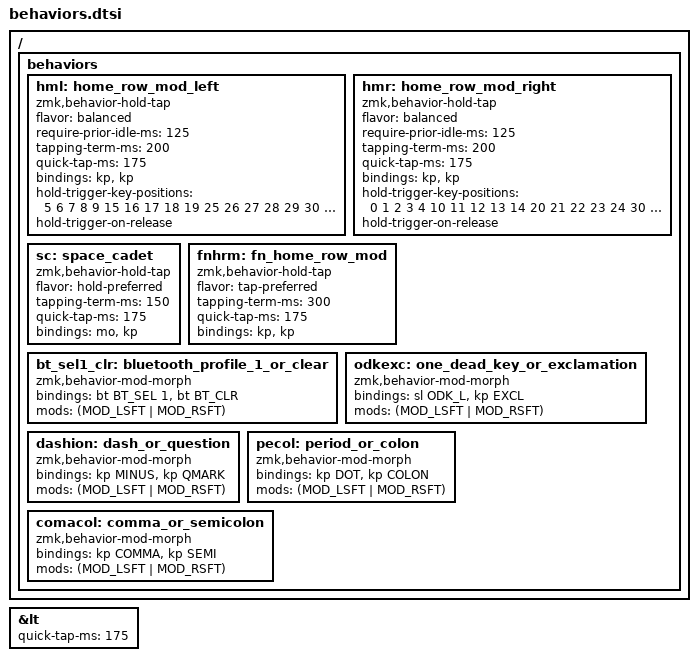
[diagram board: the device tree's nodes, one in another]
#include <behaviors.dtsi>

// Keep home-row mods resistant to same-hand rolls. A hold is resolved when a
// key on the opposite hand is pressed, while fast typing remains a tap.
/ {
    behaviors {
        hml: home_row_mod_left {
            compatible = "zmk,behavior-hold-tap";
            #binding-cells = <2>;
            flavor = "balanced";
            require-prior-idle-ms = <125>;
            tapping-term-ms = <200>;
            quick-tap-ms = <175>;
            bindings = <&kp>, <&kp>;
            hold-trigger-key-positions = <5 6 7 8 9 15 16 17 18 19 25 26 27 28 29 30 31 32 33>;
            hold-trigger-on-release;
        };

        hmr: home_row_mod_right {
            compatible = "zmk,behavior-hold-tap";
            #binding-cells = <2>;
            flavor = "balanced";
            require-prior-idle-ms = <125>;
            tapping-term-ms = <200>;
            quick-tap-ms = <175>;
            bindings = <&kp>, <&kp>;
            hold-trigger-key-positions = <0 1 2 3 4 10 11 12 13 14 20 21 22 23 24 30 31 32 33>;
            hold-trigger-on-release;
        };

        // NavNum thumb keys: tap Delete/Shift+Space, hold for Fn.
        sc: space_cadet {
            compatible = "zmk,behavior-hold-tap";
            #binding-cells = <2>;
            flavor = "hold-preferred";
            tapping-term-ms = <150>;
            quick-tap-ms = <175>;
            bindings = <&mo>, <&kp>;
        };

        // Fn/media dual-role keys intentionally have no bilateral restriction,
        // allowing Shift+Bluetooth Clear while Fn is held by both thumbs.
        fnhrm: fn_home_row_mod {
            compatible = "zmk,behavior-hold-tap";
            #binding-cells = <2>;
            flavor = "tap-preferred";
            tapping-term-ms = <300>;
            quick-tap-ms = <175>;
            bindings = <&kp>, <&kp>;
        };

        bt_sel1_clr: bluetooth_profile_1_or_clear {
            compatible = "zmk,behavior-mod-morph";
            #binding-cells = <0>;
            bindings = <&bt BT_SEL 1>, <&bt BT_CLR>;
            mods = <(MOD_LSFT | MOD_RSFT)>;
        };

        // Ergo-L's One Dead Key enters the accent layer unless shifted.
        odkexc: one_dead_key_or_exclamation {
            compatible = "zmk,behavior-mod-morph";
            #binding-cells = <0>;
            bindings = <&sl ODK_L>, <&kp EXCL>;
            mods = <(MOD_LSFT | MOD_RSFT)>;
        };

        dashion: dash_or_question {
            compatible = "zmk,behavior-mod-morph";
            #binding-cells = <0>;
            bindings = <&kp MINUS>, <&kp QMARK>;
            mods = <(MOD_LSFT | MOD_RSFT)>;
        };

        pecol: period_or_colon {
            compatible = "zmk,behavior-mod-morph";
            #binding-cells = <0>;
            bindings = <&kp DOT>, <&kp COLON>;
            mods = <(MOD_LSFT | MOD_RSFT)>;
        };

        comacol: comma_or_semicolon {
            compatible = "zmk,behavior-mod-morph";
            #binding-cells = <0>;
            bindings = <&kp COMMA>, <&kp SEMI>;
            mods = <(MOD_LSFT | MOD_RSFT)>;
        };
    };
};

// Repeating Space/Backspace should continue to feel like ordinary keys.
&lt { quick-tap-ms = <175>; };
